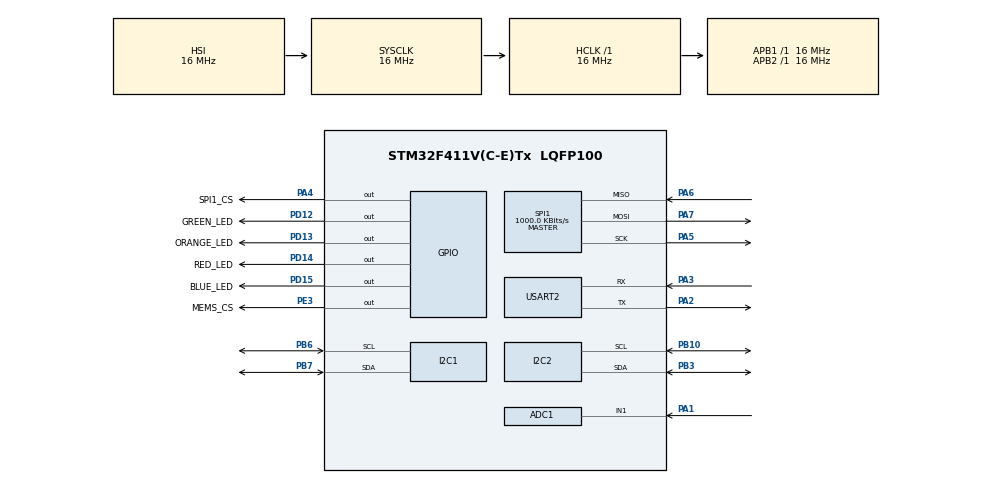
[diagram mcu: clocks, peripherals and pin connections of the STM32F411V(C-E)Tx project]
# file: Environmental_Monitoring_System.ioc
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ADC1.Channel-4\#ChannelRegularConversion=ADC_CHANNEL_1
ADC1.NbrOfConversionFlag=1
ADC1.Rank-4\#ChannelRegularConversion=1
ADC1.SamplingTime-4\#ChannelRegularConversion=ADC_SAMPLETIME_84CYCLES
ADC1.master=1
FREERTOS.Tasks01=defaultTask,24,128,StartDefaultTask,Default,NULL,Dynamic,NULL,NULL
Mcu.Family=STM32F4
Mcu.Name=STM32F411V(C-E)Tx
Mcu.Package=LQFP100
NVIC.PriorityGroup=NVIC_PRIORITYGROUP_4
NVIC.TIM1_UP_TIM10_IRQn=true\:15\:0\:false\:false\:true\:false\:false\:true\:true
NVIC.TimeBase=TIM1_UP_TIM10_IRQn
NVIC.TimeBaseIP=TIM1
NVIC.USART2_IRQn=true\:5\:0\:false\:false\:true\:true\:true\:true\:true
PA1.Signal=ADCx_IN1
PA13.Mode=Serial_Wire
PA13.Signal=SYS_JTMS-SWDIO
PA14.Mode=Serial_Wire
PA14.Signal=SYS_JTCK-SWCLK
PA2.Mode=Asynchronous
PA2.Signal=USART2_TX
PA3.Mode=Asynchronous
PA3.Signal=USART2_RX
PA4.GPIO_Label=SPI1_CS
PA4.GPIO_PuPd=GPIO_PULLUP
PA4.GPIO_Speed=GPIO_SPEED_FREQ_HIGH
PA4.PinState=GPIO_PIN_SET
PA4.Signal=GPIO_Output
PA5.Mode=Full_Duplex_Master
PA5.Signal=SPI1_SCK
PA6.Mode=Full_Duplex_Master
PA6.Signal=SPI1_MISO
PA7.Mode=Full_Duplex_Master
PA7.Signal=SPI1_MOSI
PB10.Mode=I2C
PB10.Signal=I2C2_SCL
PB3.Mode=I2C
PB3.Signal=I2C2_SDA
PB6.Mode=I2C
PB6.Signal=I2C1_SCL
PB7.Mode=I2C
PB7.Signal=I2C1_SDA
PD12.GPIO_Label=GREEN_LED
PD12.Signal=GPIO_Output
PD13.GPIO_Label=ORANGE_LED
PD13.Signal=GPIO_Output
PD14.GPIO_Label=RED_LED
PD14.Signal=GPIO_Output
PD15.GPIO_Label=BLUE_LED
PD15.Signal=GPIO_Output
PE3.GPIO_Label=MEMS_CS
PE3.PinState=GPIO_PIN_SET
PE3.Signal=GPIO_Output
ProjectManager.HeapSize=0x200
ProjectManager.StackSize=0x400
ProjectManager.TargetToolchain=STM32CubeIDE
RCC.AHBFreq_Value=16000000
RCC.APB1Freq_Value=16000000
RCC.APB2Freq_Value=16000000
RCC.CortexFreq_Value=16000000
RCC.HSE_VALUE=25000000
RCC.HSI_VALUE=16000000
RCC.LSE_VALUE=32768
RCC.SYSCLKFreq_VALUE=16000000
RCC.VCOOutputFreq_Value=192000000
RTC.Format=RTC_FORMAT_BIN
RTC.SynchPrediv=249
RTC.Year=26
SH.ADCx_IN1.0=ADC1_IN1,IN1
SPI1.BaudRatePrescaler=SPI_BAUDRATEPRESCALER_16
SPI1.CalculateBaudRate=1000.0 KBits/s
SPI1.Direction=SPI_DIRECTION_2LINES
SPI1.Mode=SPI_MODE_MASTER
SPI1.VirtualType=VM_MASTER
USART2.VirtualMode=VM_ASYNC
VP_FREERTOS_VS_CMSIS_V2.Mode=CMSIS_V2
VP_RTC_VS_RTC_Activate.Mode=RTC_Enabled
VP_RTC_VS_RTC_Calendar.Mode=RTC_Calendar
VP_SYS_VS_tim1.Mode=TIM1
board=custom

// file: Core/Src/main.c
/* USER CODE BEGIN Header */
/**
  ******************************************************************************
  * @file           : main.c
  * @brief          : Main program body
  ******************************************************************************
  * @attention
  *
  * Copyright (c) 2026 STMicroelectronics.
  * All rights reserved.
  *
  * This software is licensed under terms that can be found in the LICENSE file
  * in the root directory of this software component.
  * If no LICENSE file comes with this software, it is provided AS-IS.
  *
  ******************************************************************************
  */
/* USER CODE END Header */
#include "main.h"
#include "cmsis_os.h"

/* USER CODE BEGIN Includes */
#include "app_main.h"
/* USER CODE END Includes */

ADC_HandleTypeDef hadc1;

I2C_HandleTypeDef hi2c1;
I2C_HandleTypeDef hi2c2;

RTC_HandleTypeDef hrtc;

SPI_HandleTypeDef hspi1;

UART_HandleTypeDef huart2;

/* Definitions for defaultTask */
osThreadId_t defaultTaskHandle;
const osThreadAttr_t defaultTask_attributes = {
  .name = "defaultTask",
  .stack_size = 128 * 4,
  .priority = (osPriority_t) osPriorityLow,
};

void SystemClock_Config(void);
static void MX_GPIO_Init(void);
static void MX_I2C1_Init(void);
static void MX_I2C2_Init(void);
static void MX_SPI1_Init(void);
static void MX_USART2_UART_Init(void);
static void MX_ADC1_Init(void);
static void MX_RTC_Init(void);
void StartDefaultTask(void *argument);

int main(void)
{

  /* MCU Configuration--------------------------------------------------------*/

  /* Reset of all peripherals, Initializes the Flash interface and the Systick. */
  HAL_Init();

  /* Configure the system clock */
  SystemClock_Config();

  /* Initialize all configured peripherals */
  MX_GPIO_Init();
  MX_I2C1_Init();
  MX_I2C2_Init();
  MX_SPI1_Init();
  MX_USART2_UART_Init();
  MX_ADC1_Init();
  MX_RTC_Init();

  /* Init scheduler */
  osKernelInitialize();

  /* Create the thread(s) */
  /* creation of defaultTask */
  defaultTaskHandle = osThreadNew(StartDefaultTask, NULL, &defaultTask_attributes);

  /* USER CODE BEGIN RTOS_THREADS */
  /* add threads, ... */
  app_init();
  /* USER CODE END RTOS_THREADS */

  /* Start scheduler */
  osKernelStart();

  /* We should never get here as control is now taken by the scheduler */

  /* Infinite loop */
  while (1)
  {

  }
}

void SystemClock_Config(void)
{
  RCC_OscInitTypeDef RCC_OscInitStruct = {0};
  RCC_ClkInitTypeDef RCC_ClkInitStruct = {0};

  /** Configure the main internal regulator output voltage
  */
  __HAL_RCC_PWR_CLK_ENABLE();
  __HAL_PWR_VOLTAGESCALING_CONFIG(PWR_REGULATOR_VOLTAGE_SCALE1);

  /** Initializes the RCC Oscillators according to the specified parameters
  * in the RCC_OscInitTypeDef structure.
  */
  RCC_OscInitStruct.OscillatorType = RCC_OSCILLATORTYPE_HSI|RCC_OSCILLATORTYPE_LSI;
  RCC_OscInitStruct.HSIState = RCC_HSI_ON;
  RCC_OscInitStruct.HSICalibrationValue = RCC_HSICALIBRATION_DEFAULT;
  RCC_OscInitStruct.LSIState = RCC_LSI_ON;
  RCC_OscInitStruct.PLL.PLLState = RCC_PLL_NONE;
  if (HAL_RCC_OscConfig(&RCC_OscInitStruct) != HAL_OK)
  {
    Error_Handler();
  }

  /** Initializes the CPU, AHB and APB buses clocks
  */
  RCC_ClkInitStruct.ClockType = RCC_CLOCKTYPE_HCLK|RCC_CLOCKTYPE_SYSCLK
                              |RCC_CLOCKTYPE_PCLK1|RCC_CLOCKTYPE_PCLK2;
  RCC_ClkInitStruct.SYSCLKSource = RCC_SYSCLKSOURCE_HSI;
  RCC_ClkInitStruct.AHBCLKDivider = RCC_SYSCLK_DIV1;
  RCC_ClkInitStruct.APB1CLKDivider = RCC_HCLK_DIV1;
  RCC_ClkInitStruct.APB2CLKDivider = RCC_HCLK_DIV1;

  if (HAL_RCC_ClockConfig(&RCC_ClkInitStruct, FLASH_LATENCY_0) != HAL_OK)
  {
    Error_Handler();
  }
}

static void MX_ADC1_Init(void)
{

  ADC_ChannelConfTypeDef sConfig = {0};

  /** Configure the global features of the ADC (Clock, Resolution, Data Alignment and number of conversion)
  */
  hadc1.Instance = ADC1;
  hadc1.Init.ClockPrescaler = ADC_CLOCK_SYNC_PCLK_DIV2;
  hadc1.Init.Resolution = ADC_RESOLUTION_12B;
  hadc1.Init.ScanConvMode = DISABLE;
  hadc1.Init.ContinuousConvMode = DISABLE;
  hadc1.Init.DiscontinuousConvMode = DISABLE;
  hadc1.Init.ExternalTrigConvEdge = ADC_EXTERNALTRIGCONVEDGE_NONE;
  hadc1.Init.ExternalTrigConv = ADC_SOFTWARE_START;
  hadc1.Init.DataAlign = ADC_DATAALIGN_RIGHT;
  hadc1.Init.NbrOfConversion = 1;
  hadc1.Init.DMAContinuousRequests = DISABLE;
  hadc1.Init.EOCSelection = ADC_EOC_SINGLE_CONV;
  if (HAL_ADC_Init(&hadc1) != HAL_OK)
  {
    Error_Handler();
  }

  /** Configure for the selected ADC regular channel its corresponding rank in the sequencer and its sample time.
  */
  sConfig.Channel = ADC_CHANNEL_1;
  sConfig.Rank = 1;
  sConfig.SamplingTime = ADC_SAMPLETIME_84CYCLES;
  if (HAL_ADC_ConfigChannel(&hadc1, &sConfig) != HAL_OK)
  {
    Error_Handler();
  }

}

static void MX_I2C1_Init(void)
{

  hi2c1.Instance = I2C1;
  hi2c1.Init.ClockSpeed = 100000;
  hi2c1.Init.DutyCycle = I2C_DUTYCYCLE_2;
  hi2c1.Init.OwnAddress1 = 0;
  hi2c1.Init.AddressingMode = I2C_ADDRESSINGMODE_7BIT;
  hi2c1.Init.DualAddressMode = I2C_DUALADDRESS_DISABLE;
  hi2c1.Init.OwnAddress2 = 0;
  hi2c1.Init.GeneralCallMode = I2C_GENERALCALL_DISABLE;
  hi2c1.Init.NoStretchMode = I2C_NOSTRETCH_DISABLE;
  if (HAL_I2C_Init(&hi2c1) != HAL_OK)
  {
    Error_Handler();
  }

}

static void MX_I2C2_Init(void)
{

  hi2c2.Instance = I2C2;
  hi2c2.Init.ClockSpeed = 100000;
  hi2c2.Init.DutyCycle = I2C_DUTYCYCLE_2;
  hi2c2.Init.OwnAddress1 = 0;
  hi2c2.Init.AddressingMode = I2C_ADDRESSINGMODE_7BIT;
  hi2c2.Init.DualAddressMode = I2C_DUALADDRESS_DISABLE;
  hi2c2.Init.OwnAddress2 = 0;
  hi2c2.Init.GeneralCallMode = I2C_GENERALCALL_DISABLE;
  hi2c2.Init.NoStretchMode = I2C_NOSTRETCH_DISABLE;
  if (HAL_I2C_Init(&hi2c2) != HAL_OK)
  {
    Error_Handler();
  }

}

static void MX_RTC_Init(void)
{

  RTC_TimeTypeDef sTime = {0};
  RTC_DateTypeDef sDate = {0};

  /** Initialize RTC Only
  */
  hrtc.Instance = RTC;
  hrtc.Init.HourFormat = RTC_HOURFORMAT_24;
  hrtc.Init.AsynchPrediv = 127;
  hrtc.Init.SynchPrediv = 249;
  hrtc.Init.OutPut = RTC_OUTPUT_DISABLE;
  hrtc.Init.OutPutPolarity = RTC_OUTPUT_POLARITY_HIGH;
  hrtc.Init.OutPutType = RTC_OUTPUT_TYPE_OPENDRAIN;
  if (HAL_RTC_Init(&hrtc) != HAL_OK)
  {
    Error_Handler();
  }

  /** Initialize RTC and set the Time and Date
  */
  sTime.Hours = 0;
  sTime.Minutes = 0;
  sTime.Seconds = 0;
  sTime.DayLightSaving = RTC_DAYLIGHTSAVING_NONE;
  sTime.StoreOperation = RTC_STOREOPERATION_RESET;
  if (HAL_RTC_SetTime(&hrtc, &sTime, RTC_FORMAT_BIN) != HAL_OK)
  {
    Error_Handler();
  }
  sDate.WeekDay = RTC_WEEKDAY_MONDAY;
  sDate.Month = RTC_MONTH_JANUARY;
  sDate.Date = 1;
  sDate.Year = 26;

  if (HAL_RTC_SetDate(&hrtc, &sDate, RTC_FORMAT_BIN) != HAL_OK)
  {
    Error_Handler();
  }

}

static void MX_SPI1_Init(void)
{

  /* SPI1 parameter configuration*/
  hspi1.Instance = SPI1;
  hspi1.Init.Mode = SPI_MODE_MASTER;
  hspi1.Init.Direction = SPI_DIRECTION_2LINES;
  hspi1.Init.DataSize = SPI_DATASIZE_8BIT;
  hspi1.Init.CLKPolarity = SPI_POLARITY_LOW;
  hspi1.Init.CLKPhase = SPI_PHASE_1EDGE;
  hspi1.Init.NSS = SPI_NSS_SOFT;
  hspi1.Init.BaudRatePrescaler = SPI_BAUDRATEPRESCALER_16;
  hspi1.Init.FirstBit = SPI_FIRSTBIT_MSB;
  hspi1.Init.TIMode = SPI_TIMODE_DISABLE;
  hspi1.Init.CRCCalculation = SPI_CRCCALCULATION_DISABLE;
  hspi1.Init.CRCPolynomial = 10;
  if (HAL_SPI_Init(&hspi1) != HAL_OK)
  {
    Error_Handler();
  }

}

static void MX_USART2_UART_Init(void)
{

  huart2.Instance = USART2;
  huart2.Init.BaudRate = 115200;
  huart2.Init.WordLength = UART_WORDLENGTH_8B;
  huart2.Init.StopBits = UART_STOPBITS_1;
  huart2.Init.Parity = UART_PARITY_NONE;
  huart2.Init.Mode = UART_MODE_TX_RX;
  huart2.Init.HwFlowCtl = UART_HWCONTROL_NONE;
  huart2.Init.OverSampling = UART_OVERSAMPLING_16;
  if (HAL_UART_Init(&huart2) != HAL_OK)
  {
    Error_Handler();
  }

}

static void MX_GPIO_Init(void)
{
  GPIO_InitTypeDef GPIO_InitStruct = {0};

  /* GPIO Ports Clock Enable */
  __HAL_RCC_GPIOE_CLK_ENABLE();
  __HAL_RCC_GPIOA_CLK_ENABLE();
  __HAL_RCC_GPIOB_CLK_ENABLE();
  __HAL_RCC_GPIOD_CLK_ENABLE();

  /*Configure GPIO pin Output Level */
  HAL_GPIO_WritePin(MEMS_CS_GPIO_Port, MEMS_CS_Pin, GPIO_PIN_SET);

  /*Configure GPIO pin Output Level */
  HAL_GPIO_WritePin(SPI1_CS_GPIO_Port, SPI1_CS_Pin, GPIO_PIN_SET);

  /*Configure GPIO pin Output Level */
  HAL_GPIO_WritePin(GPIOD, GREEN_LED_Pin|ORANGE_LED_Pin|RED_LED_Pin|BLUE_LED_Pin, GPIO_PIN_RESET);

  /*Configure GPIO pin : MEMS_CS_Pin */
  GPIO_InitStruct.Pin = MEMS_CS_Pin;
  GPIO_InitStruct.Mode = GPIO_MODE_OUTPUT_PP;
  GPIO_InitStruct.Pull = GPIO_NOPULL;
  GPIO_InitStruct.Speed = GPIO_SPEED_FREQ_LOW;
  HAL_GPIO_Init(MEMS_CS_GPIO_Port, &GPIO_InitStruct);

  /*Configure GPIO pin : SPI1_CS_Pin */
  GPIO_InitStruct.Pin = SPI1_CS_Pin;
  GPIO_InitStruct.Mode = GPIO_MODE_OUTPUT_PP;
  GPIO_InitStruct.Pull = GPIO_PULLUP;
  GPIO_InitStruct.Speed = GPIO_SPEED_FREQ_HIGH;
  HAL_GPIO_Init(SPI1_CS_GPIO_Port, &GPIO_InitStruct);

  /*Configure GPIO pins : GREEN_LED_Pin ORANGE_LED_Pin RED_LED_Pin BLUE_LED_Pin */
  GPIO_InitStruct.Pin = GREEN_LED_Pin|ORANGE_LED_Pin|RED_LED_Pin|BLUE_LED_Pin;
  GPIO_InitStruct.Mode = GPIO_MODE_OUTPUT_PP;
  GPIO_InitStruct.Pull = GPIO_NOPULL;
  GPIO_InitStruct.Speed = GPIO_SPEED_FREQ_LOW;
  HAL_GPIO_Init(GPIOD, &GPIO_InitStruct);

}

void StartDefaultTask(void *argument)
{
  /* USER CODE BEGIN 5 */
  /* Infinite loop */
  for(;;)
  {
	  HAL_GPIO_TogglePin(GPIOD, GREEN_LED_Pin);
	  osDelay(1000);
  }
  /* USER CODE END 5 */
}

void HAL_TIM_PeriodElapsedCallback(TIM_HandleTypeDef *htim)
{
  if (htim->Instance == TIM1)
  {
    HAL_IncTick();
  }
}

void Error_Handler(void)
{
  __disable_irq();
  while (1)
  {
  }
}
